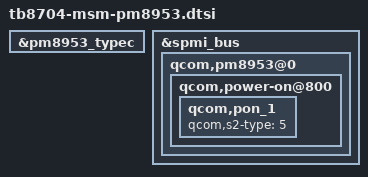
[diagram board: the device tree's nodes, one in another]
&pm8953_typec {
    /delete-property/ ss-mux-supply;
};

&spmi_bus {
	qcom,pm8953@0 {
		qcom,power-on@800 {
			qcom,pon_1 {
				qcom,s2-type = <5>;//soft(0) warm(1) shutdown(4) hard (7);
			};
		};
	};
};
